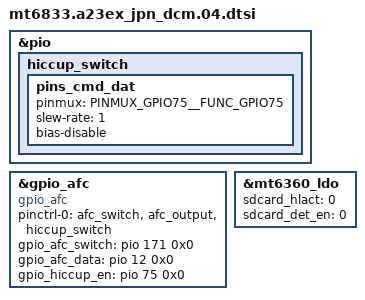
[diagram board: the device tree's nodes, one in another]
/*
 * Generated by Samsung
 * If these files should be changed, then please make a sync with MTK
*/

#include "mt6833-a23ex_common.dtsi"

// Camera DT
#include "mt6833-a23ex_camera_02.dtsi"

&pio {
	hiccup_switch: hiccup_switch {
		pins_cmd_dat {
			pinmux = <PINMUX_GPIO75__FUNC_GPIO75>;
			slew-rate = <1>;
			bias-disable;
		};
	};
};

&gpio_afc {
	compatible = "gpio_afc";
	pinctrl-names = "default";
	pinctrl-0 = <&afc_switch &afc_output &hiccup_switch>;
	status = "okay";
	gpio_afc_switch = <&pio 171 0x0>;
	gpio_afc_data = <&pio 12 0x0>;
	gpio_hiccup_en = <&pio 75 0x0>;
};

&mt6360_ldo {
	sdcard_hlact = <0>;
	sdcard_det_en = <0>;
};

/*End of this file, DO NOT ADD ANYTHING HERE*/
